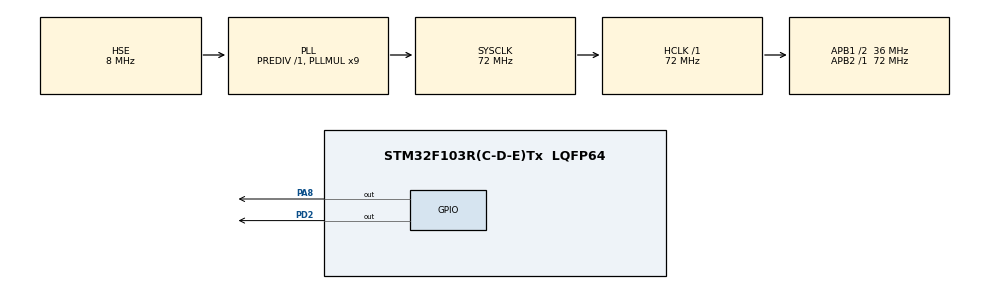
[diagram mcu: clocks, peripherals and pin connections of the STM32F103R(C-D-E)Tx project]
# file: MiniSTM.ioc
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FREERTOS.Tasks01=defaultTask,24,128,StartDefaultTask,Default,NULL,Dynamic,NULL,NULL;led0Task,8,128,StartLed0Task,As weak,NULL,Dynamic,NULL,NULL;led1Task,8,128,StartLed1Task,As weak,NULL,Dynamic,NULL,NULL
Mcu.Family=STM32F1
Mcu.Name=STM32F103R(C-D-E)Tx
Mcu.Package=LQFP64
NVIC.PriorityGroup=NVIC_PRIORITYGROUP_4
NVIC.TIM7_IRQn=true\:15\:0\:false\:false\:true\:false\:false\:true\:true
NVIC.TimeBase=TIM7_IRQn
NVIC.TimeBaseIP=TIM7
PA13.Mode=Serial_Wire
PA13.Signal=SYS_JTMS-SWDIO
PA14.Mode=Serial_Wire
PA14.Signal=SYS_JTCK-SWCLK
PA8.GPIO_PuPd=GPIO_PULLUP
PA8.Signal=GPIO_Output
PC14-OSC32_IN.Mode=LSE-External-Oscillator
PC14-OSC32_IN.Signal=RCC_OSC32_IN
PC15-OSC32_OUT.Mode=LSE-External-Oscillator
PC15-OSC32_OUT.Signal=RCC_OSC32_OUT
PD0-OSC_IN.Mode=HSE-External-Oscillator
PD0-OSC_IN.Signal=RCC_OSC_IN
PD1-OSC_OUT.Mode=HSE-External-Oscillator
PD1-OSC_OUT.Signal=RCC_OSC_OUT
PD2.GPIO_PuPd=GPIO_PULLUP
PD2.Signal=GPIO_Output
ProjectManager.HeapSize=0x200
ProjectManager.StackSize=0x400
ProjectManager.TargetToolchain=MDK-ARM V5.32
RCC.AHBFreq_Value=72000000
RCC.APB1CLKDivider=RCC_HCLK_DIV2
RCC.APB1Freq_Value=36000000
RCC.APB1TimFreq_Value=72000000
RCC.APB2Freq_Value=72000000
RCC.APB2TimFreq_Value=72000000
RCC.HCLKFreq_Value=72000000
RCC.PLLMUL=RCC_PLL_MUL9
RCC.PLLSourceVirtual=RCC_PLLSOURCE_HSE
RCC.SYSCLKFreq_VALUE=72000000
RCC.SYSCLKSource=RCC_SYSCLKSOURCE_PLLCLK
RCC.USBFreq_Value=72000000
VP_FREERTOS_VS_CMSIS_V2.Mode=CMSIS_V2
VP_SYS_VS_tim7.Mode=TIM7
board=custom

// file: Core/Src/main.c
/* USER CODE BEGIN Header */
/**
  ******************************************************************************
  * @file           : main.c
  * @brief          : Main program body
  ******************************************************************************
  * @attention
  *
  * Copyright (c) 2022 STMicroelectronics.
  * All rights reserved.
  *
  * This software is licensed under terms that can be found in the LICENSE file
  * in the root directory of this software component.
  * If no LICENSE file comes with this software, it is provided AS-IS.
  *
  ******************************************************************************
  */
/* USER CODE END Header */
#include "main.h"
#include "cmsis_os.h"
#include "gpio.h"

void SystemClock_Config(void);
void MX_FREERTOS_Init(void);

/* USER CODE BEGIN 0 */
void StartLed0Task(void *argument)
{
	osDelay(500);
  for(;;)
  {
		HAL_GPIO_WritePin(GPIOA,GPIO_PIN_8,GPIO_PIN_RESET);
		osDelay(500);
		HAL_GPIO_WritePin(GPIOA,GPIO_PIN_8,GPIO_PIN_SET);
    osDelay(500);
  }
}
void StartLed1Task(void *argument)
{
  for(;;)
  {
		osDelay(500);
		HAL_GPIO_WritePin(GPIOD,GPIO_PIN_2,GPIO_PIN_SET);
		osDelay(500);
		HAL_GPIO_WritePin(GPIOD,GPIO_PIN_2,GPIO_PIN_RESET);
  }
}
/* USER CODE END 0 */

int main(void)
{

  /* MCU Configuration--------------------------------------------------------*/

  /* Reset of all peripherals, Initializes the Flash interface and the Systick. */
  HAL_Init();

  /* Configure the system clock */
  SystemClock_Config();

  /* Initialize all configured peripherals */
  MX_GPIO_Init();

  /* Init scheduler */
  osKernelInitialize();  /* Call init function for freertos objects (in freertos.c) */
  MX_FREERTOS_Init();

  /* Start scheduler */
  osKernelStart();

  /* We should never get here as control is now taken by the scheduler */
  /* Infinite loop */
  while (1)
  {

  }
}

void SystemClock_Config(void)
{
  RCC_OscInitTypeDef RCC_OscInitStruct = {0};
  RCC_ClkInitTypeDef RCC_ClkInitStruct = {0};

  /** Initializes the RCC Oscillators according to the specified parameters
  * in the RCC_OscInitTypeDef structure.
  */
  RCC_OscInitStruct.OscillatorType = RCC_OSCILLATORTYPE_HSE;
  RCC_OscInitStruct.HSEState = RCC_HSE_ON;
  RCC_OscInitStruct.HSEPredivValue = RCC_HSE_PREDIV_DIV1;
  RCC_OscInitStruct.HSIState = RCC_HSI_ON;
  RCC_OscInitStruct.PLL.PLLState = RCC_PLL_ON;
  RCC_OscInitStruct.PLL.PLLSource = RCC_PLLSOURCE_HSE;
  RCC_OscInitStruct.PLL.PLLMUL = RCC_PLL_MUL9;
  if (HAL_RCC_OscConfig(&RCC_OscInitStruct) != HAL_OK)
  {
    Error_Handler();
  }

  /** Initializes the CPU, AHB and APB buses clocks
  */
  RCC_ClkInitStruct.ClockType = RCC_CLOCKTYPE_HCLK|RCC_CLOCKTYPE_SYSCLK
                              |RCC_CLOCKTYPE_PCLK1|RCC_CLOCKTYPE_PCLK2;
  RCC_ClkInitStruct.SYSCLKSource = RCC_SYSCLKSOURCE_PLLCLK;
  RCC_ClkInitStruct.AHBCLKDivider = RCC_SYSCLK_DIV1;
  RCC_ClkInitStruct.APB1CLKDivider = RCC_HCLK_DIV2;
  RCC_ClkInitStruct.APB2CLKDivider = RCC_HCLK_DIV1;

  if (HAL_RCC_ClockConfig(&RCC_ClkInitStruct, FLASH_LATENCY_2) != HAL_OK)
  {
    Error_Handler();
  }
}

void HAL_TIM_PeriodElapsedCallback(TIM_HandleTypeDef *htim)
{
  if (htim->Instance == TIM7) {
    HAL_IncTick();
  }
}

void Error_Handler(void)
{
  __disable_irq();
  while (1)
  {
  }
}

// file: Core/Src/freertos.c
/* USER CODE BEGIN Header */
/**
  ******************************************************************************
  * File Name          : freertos.c
  * Description        : Code for freertos applications
  ******************************************************************************
  * @attention
  *
  * Copyright (c) 2022 STMicroelectronics.
  * All rights reserved.
  *
  * This software is licensed under terms that can be found in the LICENSE file
  * in the root directory of this software component.
  * If no LICENSE file comes with this software, it is provided AS-IS.
  *
  ******************************************************************************
  */
/* USER CODE END Header */

#include "FreeRTOS.h"
#include "task.h"
#include "main.h"
#include "cmsis_os.h"

/* Definitions for defaultTask */
osThreadId_t defaultTaskHandle;
const osThreadAttr_t defaultTask_attributes = {
  .name = "defaultTask",
  .stack_size = 128 * 4,
  .priority = (osPriority_t) osPriorityNormal,
};
/* Definitions for led0Task */
osThreadId_t led0TaskHandle;
const osThreadAttr_t led0Task_attributes = {
  .name = "led0Task",
  .stack_size = 128 * 4,
  .priority = (osPriority_t) osPriorityLow,
};
/* Definitions for led1Task */
osThreadId_t led1TaskHandle;
const osThreadAttr_t led1Task_attributes = {
  .name = "led1Task",
  .stack_size = 128 * 4,
  .priority = (osPriority_t) osPriorityLow,
};

void StartDefaultTask(void *argument);
void StartLed0Task(void *argument);
void StartLed1Task(void *argument);

void MX_FREERTOS_Init(void); /* (MISRA C 2004 rule 8.1) */

void MX_FREERTOS_Init(void) {

  /* Create the thread(s) */
  /* creation of defaultTask */
  defaultTaskHandle = osThreadNew(StartDefaultTask, NULL, &defaultTask_attributes);

  /* creation of led0Task */
  led0TaskHandle = osThreadNew(StartLed0Task, NULL, &led0Task_attributes);

  /* creation of led1Task */
  led1TaskHandle = osThreadNew(StartLed1Task, NULL, &led1Task_attributes);

}

void StartDefaultTask(void *argument)
{
  for(;;)
  {
    osDelay(1);
  }
}

__weak void StartLed0Task(void *argument)
{
  for(;;)
  {
    osDelay(1);
  }
}

__weak void StartLed1Task(void *argument)
{
  for(;;)
  {
    osDelay(1);
  }
}
